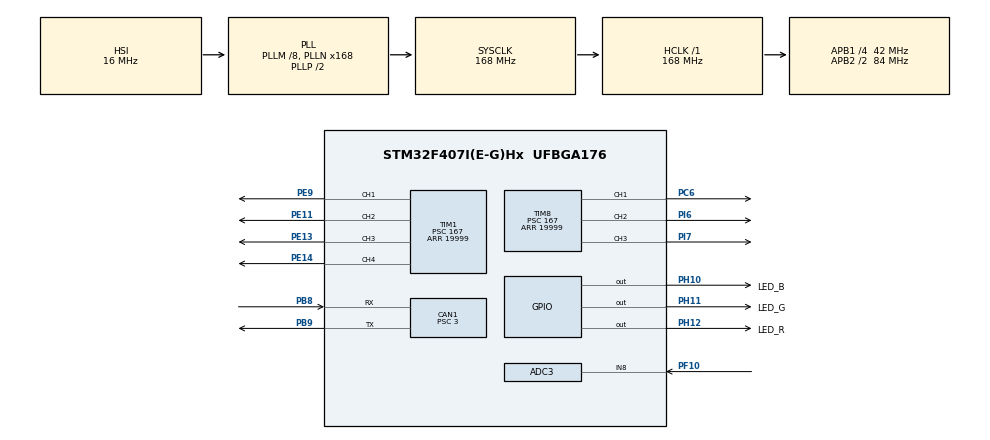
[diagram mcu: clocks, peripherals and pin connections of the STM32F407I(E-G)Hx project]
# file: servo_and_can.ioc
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ADC3.Channel-0\#ChannelRegularConversion=ADC_CHANNEL_8
ADC3.NbrOfConversionFlag=1
ADC3.Rank-0\#ChannelRegularConversion=1
ADC3.SamplingTime-0\#ChannelRegularConversion=ADC_SAMPLETIME_3CYCLES
CAN1.BS1=CAN_BS1_9TQ
CAN1.BS2=CAN_BS2_4TQ
CAN1.CalculateBaudRate=1000000
CAN1.CalculateTimeBit=1000
CAN1.CalculateTimeQuantum=71.42857142857143
CAN1.Prescaler=3
Mcu.Family=STM32F4
Mcu.Name=STM32F407I(E-G)Hx
Mcu.Package=UFBGA176
NVIC.PriorityGroup=NVIC_PRIORITYGROUP_4
PA13.Mode=Serial_Wire
PA13.Signal=SYS_JTMS-SWDIO
PA14.Mode=Serial_Wire
PA14.Signal=SYS_JTCK-SWCLK
PB8.Mode=CAN_Activate
PB8.Signal=CAN1_RX
PB9.Mode=CAN_Activate
PB9.Signal=CAN1_TX
PC6.Signal=S_TIM8_CH1
PE11.Signal=S_TIM1_CH2
PE13.Signal=S_TIM1_CH3
PE14.Signal=S_TIM1_CH4
PE9.Signal=S_TIM1_CH1
PF10.Mode=IN8
PF10.Signal=ADC3_IN8
PH0-OSC_IN.Mode=HSE-External-Oscillator
PH0-OSC_IN.Signal=RCC_OSC_IN
PH1-OSC_OUT.Mode=HSE-External-Oscillator
PH1-OSC_OUT.Signal=RCC_OSC_OUT
PH10.GPIO_Label=LED_B
PH10.Signal=GPIO_Output
PH11.GPIO_Label=LED_G
PH11.Signal=GPIO_Output
PH12.GPIO_Label=LED_R
PH12.Signal=GPIO_Output
PI6.Signal=S_TIM8_CH2
PI7.Signal=S_TIM8_CH3
ProjectManager.HeapSize=0x200
ProjectManager.StackSize=0x400
ProjectManager.TargetToolchain=MDK-ARM V5.32
RCC.48MHZClocksFreq_Value=84000000
RCC.AHBFreq_Value=168000000
RCC.APB1CLKDivider=RCC_HCLK_DIV4
RCC.APB1Freq_Value=42000000
RCC.APB1TimFreq_Value=84000000
RCC.APB2CLKDivider=RCC_HCLK_DIV2
RCC.APB2Freq_Value=84000000
RCC.APB2TimFreq_Value=168000000
RCC.CortexFreq_Value=168000000
RCC.HCLKFreq_Value=168000000
RCC.HSE_VALUE=25000000
RCC.HSI_VALUE=16000000
RCC.LSE_VALUE=32768
RCC.PLLM=8
RCC.PLLN=168
RCC.SYSCLKFreq_VALUE=168000000
RCC.SYSCLKSource=RCC_SYSCLKSOURCE_PLLCLK
RCC.VCOOutputFreq_Value=336000000
SH.S_TIM1_CH1.0=TIM1_CH1,PWM Generation1 CH1
SH.S_TIM1_CH2.0=TIM1_CH2,PWM Generation2 CH2
SH.S_TIM1_CH3.0=TIM1_CH3,PWM Generation3 CH3
SH.S_TIM1_CH4.0=TIM1_CH4,PWM Generation4 CH4
SH.S_TIM8_CH1.0=TIM8_CH1,PWM Generation1 CH1
SH.S_TIM8_CH2.0=TIM8_CH2,PWM Generation2 CH2
SH.S_TIM8_CH3.0=TIM8_CH3,PWM Generation3 CH3
TIM1.Channel-PWM\ Generation1\ CH1=TIM_CHANNEL_1
TIM1.Channel-PWM\ Generation2\ CH2=TIM_CHANNEL_2
TIM1.Channel-PWM\ Generation3\ CH3=TIM_CHANNEL_3
TIM1.Channel-PWM\ Generation4\ CH4=TIM_CHANNEL_4
TIM1.Period=19999
TIM1.Prescaler=167
TIM1.Pulse-PWM\ Generation1\ CH1=1500
TIM1.Pulse-PWM\ Generation2\ CH2=1500
TIM1.Pulse-PWM\ Generation3\ CH3=1500
TIM1.Pulse-PWM\ Generation4\ CH4=1500
TIM8.Channel-PWM\ Generation1\ CH1=TIM_CHANNEL_1
TIM8.Channel-PWM\ Generation2\ CH2=TIM_CHANNEL_2
TIM8.Channel-PWM\ Generation3\ CH3=TIM_CHANNEL_3
TIM8.Period=19999
TIM8.Prescaler=167
TIM8.Pulse-PWM\ Generation1\ CH1=1500
TIM8.Pulse-PWM\ Generation2\ CH2=1500
TIM8.Pulse-PWM\ Generation3\ CH3=1500
board=custom

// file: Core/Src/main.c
/* USER CODE BEGIN Header */
/**
  ******************************************************************************
  * @file           : main.c
  * @brief          : Main program body
  ******************************************************************************
  * @attention
  *
  * Copyright (c) 2026 STMicroelectronics.
  * All rights reserved.
  *
  * This software is licensed under terms that can be found in the LICENSE file
  * in the root directory of this software component.
  * If no LICENSE file comes with this software, it is provided AS-IS.
  *
  ******************************************************************************
  */
/* USER CODE END Header */
#include "main.h"
#include "adc.h"
#include "can.h"
#include "tim.h"
#include "gpio.h"

/* USER CODE BEGIN Includes */
#include "servo.h"
#include "can_receive_send.h"
/* USER CODE END Includes */

void SystemClock_Config(void);

int main(void)
{

  /* MCU Configuration--------------------------------------------------------*/

  /* Reset of all peripherals, Initializes the Flash interface and the Systick. */
  HAL_Init();

  /* Configure the system clock */
  SystemClock_Config();

  /* Initialize all configured peripherals */
  MX_GPIO_Init();
  MX_CAN1_Init();
  MX_TIM1_Init();
  MX_TIM8_Init();
  MX_ADC3_Init();
  /* USER CODE BEGIN 2 */
  if (servo_init(&htim1, TIM_CHANNEL_1) != HAL_OK ||
      servo_init(&htim1, TIM_CHANNEL_2) != HAL_OK ||
      servo_init(&htim1, TIM_CHANNEL_3) != HAL_OK ||
      servo_init(&htim1, TIM_CHANNEL_4) != HAL_OK ||
      servo_init(&htim8, TIM_CHANNEL_1) != HAL_OK ||
      servo_init(&htim8, TIM_CHANNEL_2) != HAL_OK ||
      servo_init(&htim8, TIM_CHANNEL_3) != HAL_OK)
  {
    Error_Handler();
  }
  CAN_App_Init();
  /* USER CODE END 2 */

  /* Infinite loop */
  while (1)
  {

    /* USER CODE BEGIN 3 */
    CAN_App_Process();
  }
  /* USER CODE END 3 */
}

void SystemClock_Config(void)
{
  RCC_OscInitTypeDef RCC_OscInitStruct = {0};
  RCC_ClkInitTypeDef RCC_ClkInitStruct = {0};

  /** Configure the main internal regulator output voltage
  */
  __HAL_RCC_PWR_CLK_ENABLE();
  __HAL_PWR_VOLTAGESCALING_CONFIG(PWR_REGULATOR_VOLTAGE_SCALE1);

  /** Initializes the RCC Oscillators according to the specified parameters
  * in the RCC_OscInitTypeDef structure.
  */
  RCC_OscInitStruct.OscillatorType = RCC_OSCILLATORTYPE_HSI;
  RCC_OscInitStruct.HSIState = RCC_HSI_ON;
  RCC_OscInitStruct.HSICalibrationValue = RCC_HSICALIBRATION_DEFAULT;
  RCC_OscInitStruct.PLL.PLLState = RCC_PLL_ON;
  RCC_OscInitStruct.PLL.PLLSource = RCC_PLLSOURCE_HSI;
  RCC_OscInitStruct.PLL.PLLM = 8;
  RCC_OscInitStruct.PLL.PLLN = 168;
  RCC_OscInitStruct.PLL.PLLP = RCC_PLLP_DIV2;
  RCC_OscInitStruct.PLL.PLLQ = 4;
  if (HAL_RCC_OscConfig(&RCC_OscInitStruct) != HAL_OK)
  {
    Error_Handler();
  }

  /** Initializes the CPU, AHB and APB buses clocks
  */
  RCC_ClkInitStruct.ClockType = RCC_CLOCKTYPE_HCLK|RCC_CLOCKTYPE_SYSCLK
                              |RCC_CLOCKTYPE_PCLK1|RCC_CLOCKTYPE_PCLK2;
  RCC_ClkInitStruct.SYSCLKSource = RCC_SYSCLKSOURCE_PLLCLK;
  RCC_ClkInitStruct.AHBCLKDivider = RCC_SYSCLK_DIV1;
  RCC_ClkInitStruct.APB1CLKDivider = RCC_HCLK_DIV4;
  RCC_ClkInitStruct.APB2CLKDivider = RCC_HCLK_DIV2;

  if (HAL_RCC_ClockConfig(&RCC_ClkInitStruct, FLASH_LATENCY_5) != HAL_OK)
  {
    Error_Handler();
  }
}

void Error_Handler(void)
{
  __disable_irq();
  while (1)
  {
  }
}
